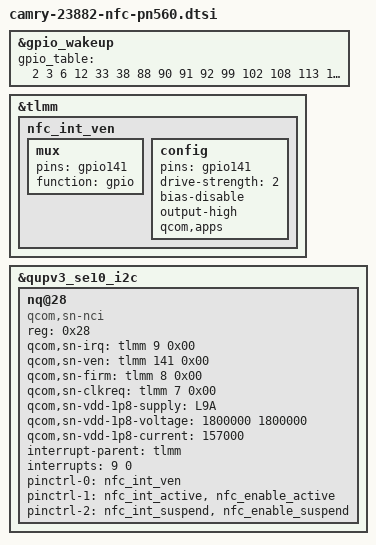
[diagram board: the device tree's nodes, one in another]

&gpio_wakeup {
	gpio_table = <2 3 6 12 33 38 88 90 91 92 99 102 108 113 114 115 116
                              48 51 59 84 85 86 107 117 118 152 153 154 155>;
};

&tlmm {
    nfc_int_ven: nfc_int_ven {
	mux {
		pins = "gpio141";
		function = "gpio";
	};

	config {
		pins = "gpio141";
		drive-strength = <2>; /* 2 MA */
                bias-disable;
                output-high;
                qcom,apps;
	};
    };
};

&qupv3_se10_i2c {
	status = "ok";
	#address-cells = <1>;
	#size-cells = <0>;
	nq@28 {
		compatible = "qcom,sn-nci";
		reg = <0x28>;
		qcom,sn-irq = <&tlmm 9 0x00>;
		qcom,sn-ven = <&tlmm 141 0x00>;
		qcom,sn-firm = <&tlmm 8 0x00>;
		qcom,sn-clkreq = <&tlmm 7 0x00>;
		qcom,sn-vdd-1p8-supply = <&L9A>;
		qcom,sn-vdd-1p8-voltage = <1800000 1800000>;
		qcom,sn-vdd-1p8-current = <157000>;
		interrupt-parent = <&tlmm>;
		interrupts = <9 0>;
		interrupt-names = "nfc_irq";
		pinctrl-names = "default", "nfc_active", "nfc_suspend";
                pinctrl-0 = <&nfc_int_ven>;
		pinctrl-1 = <&nfc_int_active &nfc_enable_active>;
		pinctrl-2 = <&nfc_int_suspend &nfc_enable_suspend>;
	};
};

